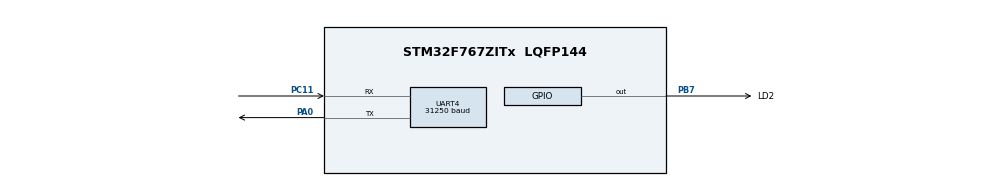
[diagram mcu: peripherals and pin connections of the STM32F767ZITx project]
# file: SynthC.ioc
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Mcu.Family=STM32F7
Mcu.Name=STM32F767ZITx
Mcu.Package=LQFP144
NVIC.PriorityGroup=NVIC_PRIORITYGROUP_4
PA0/WKUP.Mode=Asynchronous
PA0/WKUP.Signal=UART4_TX
PB7.GPIO_Label=LD2
PB7.Signal=GPIO_Output
PC11.Mode=Asynchronous
PC11.Signal=UART4_RX
PH0/OSC_IN.Mode=HSE-External-Oscillator
PH0/OSC_IN.Signal=RCC_OSC_IN
PH1/OSC_OUT.Mode=HSE-External-Oscillator
PH1/OSC_OUT.Signal=RCC_OSC_OUT
ProjectManager.HeapSize=0x200
ProjectManager.StackSize=0x400
ProjectManager.TargetToolchain=STM32CubeIDE
RCC.HSE_VALUE=25000000
RCC.HSI_VALUE=16000000
RCC.LSE_VALUE=32768
RCC.USBFreq_Value=96000000
RCC.VCOOutputFreq_Value=192000000
UART4.BaudRate=31250
board=custom

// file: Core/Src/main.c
/* USER CODE BEGIN Header */
/**
  ******************************************************************************
  * @file           : main.c
  * @brief          : Main program body
  ******************************************************************************
  * @attention
  *
  * <h2><center>&copy; Copyright (c) 2021 STMicroelectronics.
  * All rights reserved.</center></h2>
  *
  * This software component is licensed by ST under BSD 3-Clause license,
  * the "License"; You may not use this file except in compliance with the
  * License. You may obtain a copy of the License at:
  *                        opensource.org/licenses/BSD-3-Clause
  *
  ******************************************************************************
  */
/* USER CODE END Header */
#include "main.h"

UART_HandleTypeDef huart4;

void SystemClock_Config(void);
static void MX_GPIO_Init(void);
static void MX_UART4_Init(void);

int main(void)
{

  /* MCU Configuration--------------------------------------------------------*/

  /* Reset of all peripherals, Initializes the Flash interface and the Systick. */
  HAL_Init();

  /* Configure the system clock */
  SystemClock_Config();

  /* Initialize all configured peripherals */
  MX_GPIO_Init();
  MX_UART4_Init();

  /* Infinite loop */
  while (1)
  {

  }
}

void SystemClock_Config(void)
{
  RCC_OscInitTypeDef RCC_OscInitStruct = {0};
  RCC_ClkInitTypeDef RCC_ClkInitStruct = {0};
  RCC_PeriphCLKInitTypeDef PeriphClkInitStruct = {0};

  /** Configure the main internal regulator output voltage
  */
  __HAL_RCC_PWR_CLK_ENABLE();
  __HAL_PWR_VOLTAGESCALING_CONFIG(PWR_REGULATOR_VOLTAGE_SCALE3);
  /** Initializes the RCC Oscillators according to the specified parameters
  * in the RCC_OscInitTypeDef structure.
  */
  RCC_OscInitStruct.OscillatorType = RCC_OSCILLATORTYPE_HSI;
  RCC_OscInitStruct.HSIState = RCC_HSI_ON;
  RCC_OscInitStruct.HSICalibrationValue = RCC_HSICALIBRATION_DEFAULT;
  RCC_OscInitStruct.PLL.PLLState = RCC_PLL_NONE;
  if (HAL_RCC_OscConfig(&RCC_OscInitStruct) != HAL_OK)
  {
    Error_Handler();
  }
  /** Initializes the CPU, AHB and APB buses clocks
  */
  RCC_ClkInitStruct.ClockType = RCC_CLOCKTYPE_HCLK|RCC_CLOCKTYPE_SYSCLK
                              |RCC_CLOCKTYPE_PCLK1|RCC_CLOCKTYPE_PCLK2;
  RCC_ClkInitStruct.SYSCLKSource = RCC_SYSCLKSOURCE_HSI;
  RCC_ClkInitStruct.AHBCLKDivider = RCC_SYSCLK_DIV1;
  RCC_ClkInitStruct.APB1CLKDivider = RCC_HCLK_DIV1;
  RCC_ClkInitStruct.APB2CLKDivider = RCC_HCLK_DIV1;

  if (HAL_RCC_ClockConfig(&RCC_ClkInitStruct, FLASH_LATENCY_0) != HAL_OK)
  {
    Error_Handler();
  }
  PeriphClkInitStruct.PeriphClockSelection = RCC_PERIPHCLK_UART4;
  PeriphClkInitStruct.Uart4ClockSelection = RCC_UART4CLKSOURCE_PCLK1;
  if (HAL_RCCEx_PeriphCLKConfig(&PeriphClkInitStruct) != HAL_OK)
  {
    Error_Handler();
  }
}

static void MX_UART4_Init(void)
{

  huart4.Instance = UART4;
  huart4.Init.BaudRate = 31250;
  huart4.Init.WordLength = UART_WORDLENGTH_8B;
  huart4.Init.StopBits = UART_STOPBITS_1;
  huart4.Init.Parity = UART_PARITY_NONE;
  huart4.Init.Mode = UART_MODE_TX_RX;
  huart4.Init.HwFlowCtl = UART_HWCONTROL_NONE;
  huart4.Init.OverSampling = UART_OVERSAMPLING_16;
  huart4.Init.OneBitSampling = UART_ONE_BIT_SAMPLE_DISABLE;
  huart4.AdvancedInit.AdvFeatureInit = UART_ADVFEATURE_NO_INIT;
  if (HAL_UART_Init(&huart4) != HAL_OK)
  {
    Error_Handler();
  }

}

static void MX_GPIO_Init(void)
{
  GPIO_InitTypeDef GPIO_InitStruct = {0};

  /* GPIO Ports Clock Enable */
  __HAL_RCC_GPIOH_CLK_ENABLE();
  __HAL_RCC_GPIOA_CLK_ENABLE();
  __HAL_RCC_GPIOC_CLK_ENABLE();
  __HAL_RCC_GPIOB_CLK_ENABLE();

  /*Configure GPIO pin Output Level */
  HAL_GPIO_WritePin(LD2_GPIO_Port, LD2_Pin, GPIO_PIN_RESET);

  /*Configure GPIO pin : LD2_Pin */
  GPIO_InitStruct.Pin = LD2_Pin;
  GPIO_InitStruct.Mode = GPIO_MODE_OUTPUT_PP;
  GPIO_InitStruct.Pull = GPIO_NOPULL;
  GPIO_InitStruct.Speed = GPIO_SPEED_FREQ_LOW;
  HAL_GPIO_Init(LD2_GPIO_Port, &GPIO_InitStruct);

}

/* USER CODE BEGIN 4 */

void USARTx_CharReception_Callback(void)
{
 HAL_GPIO_TogglePin(LD2_GPIO_Port, LD2_Pin);
/* Read Received character. RXNE flag is cleared by reading of RDR register */
}

/* USER CODE END 4 */

void Error_Handler(void)
{
  __disable_irq();
  while (1)
  {
  }
}

/************************ (C) COPYRIGHT STMicroelectronics *****END OF FILE****/
